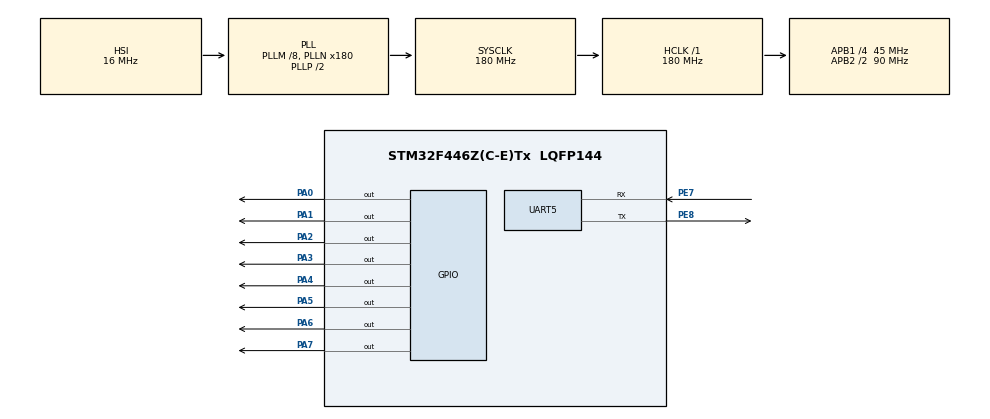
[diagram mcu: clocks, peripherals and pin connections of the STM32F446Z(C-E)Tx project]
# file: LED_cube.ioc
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Dma.Request0=UART5_RX
Dma.Request1=UART5_TX
Dma.UART5_RX.0.Direction=DMA_PERIPH_TO_MEMORY
Dma.UART5_RX.0.FIFOMode=DMA_FIFOMODE_DISABLE
Dma.UART5_RX.0.Instance=DMA1_Stream0
Dma.UART5_RX.0.MemDataAlignment=DMA_MDATAALIGN_BYTE
Dma.UART5_RX.0.MemInc=DMA_MINC_ENABLE
Dma.UART5_RX.0.Mode=DMA_NORMAL
Dma.UART5_RX.0.PeriphDataAlignment=DMA_PDATAALIGN_BYTE
Dma.UART5_RX.0.PeriphInc=DMA_PINC_DISABLE
Dma.UART5_RX.0.Priority=DMA_PRIORITY_LOW
Dma.UART5_TX.1.Direction=DMA_MEMORY_TO_PERIPH
Dma.UART5_TX.1.FIFOMode=DMA_FIFOMODE_DISABLE
Dma.UART5_TX.1.Instance=DMA1_Stream7
Dma.UART5_TX.1.MemDataAlignment=DMA_MDATAALIGN_BYTE
Dma.UART5_TX.1.MemInc=DMA_MINC_ENABLE
Dma.UART5_TX.1.Mode=DMA_NORMAL
Dma.UART5_TX.1.PeriphDataAlignment=DMA_PDATAALIGN_BYTE
Dma.UART5_TX.1.PeriphInc=DMA_PINC_DISABLE
Dma.UART5_TX.1.Priority=DMA_PRIORITY_LOW
Mcu.Family=STM32F4
Mcu.Name=STM32F446Z(C-E)Tx
Mcu.Package=LQFP144
NVIC.DMA1_Stream0_IRQn=true\:0\:0\:false\:false\:true\:false\:true\:true
NVIC.DMA1_Stream7_IRQn=true\:0\:0\:false\:false\:true\:false\:true\:true
NVIC.PriorityGroup=NVIC_PRIORITYGROUP_4
NVIC.UART5_IRQn=true\:0\:0\:false\:false\:true\:true\:true\:true
PA0-WKUP.GPIO_Speed=GPIO_SPEED_FREQ_VERY_HIGH
PA0-WKUP.Signal=GPIO_Output
PA1.GPIO_Speed=GPIO_SPEED_FREQ_VERY_HIGH
PA1.Signal=GPIO_Output
PA2.GPIO_Speed=GPIO_SPEED_FREQ_VERY_HIGH
PA2.Signal=GPIO_Output
PA3.GPIO_Speed=GPIO_SPEED_FREQ_VERY_HIGH
PA3.Signal=GPIO_Output
PA4.GPIO_Speed=GPIO_SPEED_FREQ_VERY_HIGH
PA4.Signal=GPIO_Output
PA5.GPIO_Speed=GPIO_SPEED_FREQ_VERY_HIGH
PA5.Signal=GPIO_Output
PA6.GPIO_Speed=GPIO_SPEED_FREQ_VERY_HIGH
PA6.Signal=GPIO_Output
PA7.GPIO_Speed=GPIO_SPEED_FREQ_VERY_HIGH
PA7.Signal=GPIO_Output
PE7.Mode=Asynchronous
PE7.Signal=UART5_RX
PE8.Mode=Asynchronous
PE8.Signal=UART5_TX
ProjectManager.HeapSize=0x200
ProjectManager.StackSize=0x400
ProjectManager.TargetToolchain=STM32CubeIDE
RCC.AHBFreq_Value=180000000
RCC.APB1CLKDivider=RCC_HCLK_DIV4
RCC.APB1Freq_Value=45000000
RCC.APB1TimFreq_Value=90000000
RCC.APB2CLKDivider=RCC_HCLK_DIV2
RCC.APB2Freq_Value=90000000
RCC.APB2TimFreq_Value=180000000
RCC.CortexFreq_Value=180000000
RCC.HCLKFreq_Value=180000000
RCC.PLLM=8
RCC.PLLN=180
RCC.SYSCLKFreq_VALUE=180000000
RCC.SYSCLKSource=RCC_SYSCLKSOURCE_PLLCLK
RCC.USBFreq_Value=180000000
RCC.VCOOutputFreq_Value=360000000
TIM1.Period=0xffff-1
TIM1.Prescaler=1-1
UART5.VirtualMode=Asynchronous
VP_TIM1_VS_ClockSourceINT.Mode=Internal
board=custom

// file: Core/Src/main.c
/* USER CODE BEGIN Header */
/**
  ******************************************************************************
  * @file           : main.c
  * @brief          : Main program body
  ******************************************************************************
  * @attention
  *
  * Copyright (c) 2023 STMicroelectronics.
  * All rights reserved.
  *
  * This software is licensed under terms that can be found in the LICENSE file
  * in the root directory of this software component.
  * If no LICENSE file comes with this software, it is provided AS-IS.
  *
  ******************************************************************************
  */
/* USER CODE END Header */
#include "main.h"

/* USER CODE BEGIN Includes */
#include "LED_cube.h"
/* USER CODE END Includes */

TIM_HandleTypeDef htim1;

UART_HandleTypeDef huart5;
DMA_HandleTypeDef hdma_uart5_rx;
DMA_HandleTypeDef hdma_uart5_tx;

void SystemClock_Config(void);
static void MX_GPIO_Init(void);
static void MX_DMA_Init(void);
static void MX_TIM1_Init(void);
static void MX_UART5_Init(void);

int main(void)
{

  /* MCU Configuration--------------------------------------------------------*/

  /* Reset of all peripherals, Initializes the Flash interface and the Systick. */
  HAL_Init();

  /* Configure the system clock */
  SystemClock_Config();

  /* Initialize all configured peripherals */
  MX_GPIO_Init();
  MX_DMA_Init();
  MX_TIM1_Init();
  MX_UART5_Init();
  /* USER CODE BEGIN 2 */
  HAL_TIM_Base_Start(&htim1);

  uint8_t cube_colors[CUBE_MASSIVE_SIZE + 1]; // +1 is crc8
  cube_set_zero(cube_colors);
  /* USER CODE END 2 */

  /* Infinite loop */
  /* USER CODE BEGIN WHILE */
  while(1) {
	  if(!get_cube(cube_colors)) {
		  send_cube(cube_colors);
	  }
    /* USER CODE END WHILE */

  }
}

void SystemClock_Config(void)
{
  RCC_OscInitTypeDef RCC_OscInitStruct = {0};
  RCC_ClkInitTypeDef RCC_ClkInitStruct = {0};

  /** Configure the main internal regulator output voltage
  */
  __HAL_RCC_PWR_CLK_ENABLE();
  __HAL_PWR_VOLTAGESCALING_CONFIG(PWR_REGULATOR_VOLTAGE_SCALE1);

  /** Initializes the RCC Oscillators according to the specified parameters
  * in the RCC_OscInitTypeDef structure.
  */
  RCC_OscInitStruct.OscillatorType = RCC_OSCILLATORTYPE_HSI;
  RCC_OscInitStruct.HSIState = RCC_HSI_ON;
  RCC_OscInitStruct.HSICalibrationValue = RCC_HSICALIBRATION_DEFAULT;
  RCC_OscInitStruct.PLL.PLLState = RCC_PLL_ON;
  RCC_OscInitStruct.PLL.PLLSource = RCC_PLLSOURCE_HSI;
  RCC_OscInitStruct.PLL.PLLM = 8;
  RCC_OscInitStruct.PLL.PLLN = 180;
  RCC_OscInitStruct.PLL.PLLP = RCC_PLLP_DIV2;
  RCC_OscInitStruct.PLL.PLLQ = 2;
  RCC_OscInitStruct.PLL.PLLR = 2;
  if (HAL_RCC_OscConfig(&RCC_OscInitStruct) != HAL_OK)
  {
    Error_Handler();
  }

  /** Activate the Over-Drive mode
  */
  if (HAL_PWREx_EnableOverDrive() != HAL_OK)
  {
    Error_Handler();
  }

  /** Initializes the CPU, AHB and APB buses clocks
  */
  RCC_ClkInitStruct.ClockType = RCC_CLOCKTYPE_HCLK|RCC_CLOCKTYPE_SYSCLK
                              |RCC_CLOCKTYPE_PCLK1|RCC_CLOCKTYPE_PCLK2;
  RCC_ClkInitStruct.SYSCLKSource = RCC_SYSCLKSOURCE_PLLCLK;
  RCC_ClkInitStruct.AHBCLKDivider = RCC_SYSCLK_DIV1;
  RCC_ClkInitStruct.APB1CLKDivider = RCC_HCLK_DIV4;
  RCC_ClkInitStruct.APB2CLKDivider = RCC_HCLK_DIV2;

  if (HAL_RCC_ClockConfig(&RCC_ClkInitStruct, FLASH_LATENCY_5) != HAL_OK)
  {
    Error_Handler();
  }
}

static void MX_TIM1_Init(void)
{

  TIM_ClockConfigTypeDef sClockSourceConfig = {0};
  TIM_MasterConfigTypeDef sMasterConfig = {0};

  htim1.Instance = TIM1;
  htim1.Init.Prescaler = 1-1;
  htim1.Init.CounterMode = TIM_COUNTERMODE_UP;
  htim1.Init.Period = 0xffff-1;
  htim1.Init.ClockDivision = TIM_CLOCKDIVISION_DIV1;
  htim1.Init.RepetitionCounter = 0;
  htim1.Init.AutoReloadPreload = TIM_AUTORELOAD_PRELOAD_DISABLE;
  if (HAL_TIM_Base_Init(&htim1) != HAL_OK)
  {
    Error_Handler();
  }
  sClockSourceConfig.ClockSource = TIM_CLOCKSOURCE_INTERNAL;
  if (HAL_TIM_ConfigClockSource(&htim1, &sClockSourceConfig) != HAL_OK)
  {
    Error_Handler();
  }
  sMasterConfig.MasterOutputTrigger = TIM_TRGO_RESET;
  sMasterConfig.MasterSlaveMode = TIM_MASTERSLAVEMODE_DISABLE;
  if (HAL_TIMEx_MasterConfigSynchronization(&htim1, &sMasterConfig) != HAL_OK)
  {
    Error_Handler();
  }

}

static void MX_UART5_Init(void)
{

  huart5.Instance = UART5;
  huart5.Init.BaudRate = 115200;
  huart5.Init.WordLength = UART_WORDLENGTH_8B;
  huart5.Init.StopBits = UART_STOPBITS_1;
  huart5.Init.Parity = UART_PARITY_NONE;
  huart5.Init.Mode = UART_MODE_TX_RX;
  huart5.Init.HwFlowCtl = UART_HWCONTROL_NONE;
  huart5.Init.OverSampling = UART_OVERSAMPLING_16;
  if (HAL_UART_Init(&huart5) != HAL_OK)
  {
    Error_Handler();
  }

}

static void MX_DMA_Init(void)
{

  /* DMA controller clock enable */
  __HAL_RCC_DMA1_CLK_ENABLE();

  /* DMA interrupt init */
  /* DMA1_Stream0_IRQn interrupt configuration */
  HAL_NVIC_SetPriority(DMA1_Stream0_IRQn, 0, 0);
  HAL_NVIC_EnableIRQ(DMA1_Stream0_IRQn);
  /* DMA1_Stream7_IRQn interrupt configuration */
  HAL_NVIC_SetPriority(DMA1_Stream7_IRQn, 0, 0);
  HAL_NVIC_EnableIRQ(DMA1_Stream7_IRQn);

}

static void MX_GPIO_Init(void)
{
  GPIO_InitTypeDef GPIO_InitStruct = {0};

  /* GPIO Ports Clock Enable */
  __HAL_RCC_GPIOA_CLK_ENABLE();
  __HAL_RCC_GPIOE_CLK_ENABLE();

  /*Configure GPIO pin Output Level */
  HAL_GPIO_WritePin(GPIOA, GPIO_PIN_0|GPIO_PIN_1|GPIO_PIN_2|GPIO_PIN_3
                          |GPIO_PIN_4|GPIO_PIN_5|GPIO_PIN_6|GPIO_PIN_7, GPIO_PIN_RESET);

  /*Configure GPIO pins : PA0 PA1 PA2 PA3
                           PA4 PA5 PA6 PA7 */
  GPIO_InitStruct.Pin = GPIO_PIN_0|GPIO_PIN_1|GPIO_PIN_2|GPIO_PIN_3
                          |GPIO_PIN_4|GPIO_PIN_5|GPIO_PIN_6|GPIO_PIN_7;
  GPIO_InitStruct.Mode = GPIO_MODE_OUTPUT_PP;
  GPIO_InitStruct.Pull = GPIO_NOPULL;
  GPIO_InitStruct.Speed = GPIO_SPEED_FREQ_VERY_HIGH;
  HAL_GPIO_Init(GPIOA, &GPIO_InitStruct);

}

void Error_Handler(void)
{
  __disable_irq();
  while (1)
  {
  }
}
